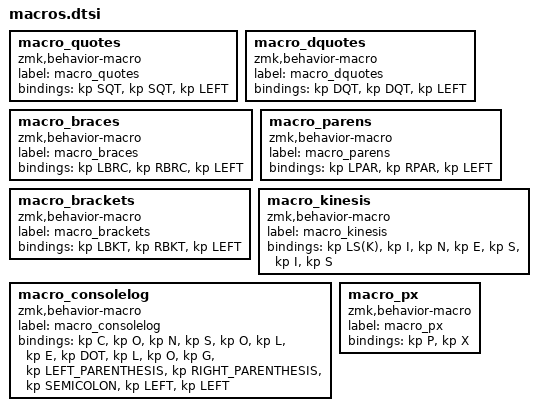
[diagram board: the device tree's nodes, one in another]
macro_quotes: macro_quotes{
compatible = "zmk,behavior-macro";
label = "macro_quotes";
#binding-cells = <0>;
bindings = <&kp SQT>, <&kp SQT>, <&kp LEFT>;
};
macro_dquotes: macro_dquotes{
compatible = "zmk,behavior-macro";
label = "macro_dquotes";
#binding-cells = <0>;
bindings = <&kp DQT>, <&kp DQT>, <&kp LEFT>;
};
macro_braces: macro_braces{
compatible = "zmk,behavior-macro";
label = "macro_braces";
#binding-cells = <0>;
bindings = <&kp LBRC>, <&kp RBRC>, <&kp LEFT>;
};
macro_parens: macro_parens{
compatible = "zmk,behavior-macro";
label = "macro_parens";
#binding-cells = <0>;
bindings = <&kp LPAR>, <&kp RPAR>, <&kp LEFT>;
};
macro_brackets: macro_brackets{
compatible = "zmk,behavior-macro";
label = "macro_brackets";
#binding-cells = <0>;
bindings = <&kp LBKT>, <&kp RBKT>, <&kp LEFT>;
};
macro_kinesis: macro_kinesis{
compatible = "zmk,behavior-macro";
label = "macro_kinesis";
#binding-cells = <0>;
bindings = <&kp LS(K)>, <&kp I>, <&kp N>, <&kp E>, <&kp S>, <&kp I>, <&kp S>;
};
macro_consolelog: macro_consolelog{
compatible = "zmk,behavior-macro";
label = "macro_consolelog";
#binding-cells = <0>;
bindings = <&kp C>, <&kp O>, <&kp N>, <&kp S>, <&kp O>, <&kp L>, <&kp E>, <&kp DOT>, <&kp L>, <&kp O>, <&kp G>, <&kp LEFT_PARENTHESIS>, <&kp RIGHT_PARENTHESIS>, <&kp SEMICOLON>, <&kp LEFT>, <&kp LEFT>;
};
macro_px: macro_px{
compatible = "zmk,behavior-macro";
label = "macro_px";
#binding-cells = <0>;
bindings = <&kp P>, <&kp X>;
};

